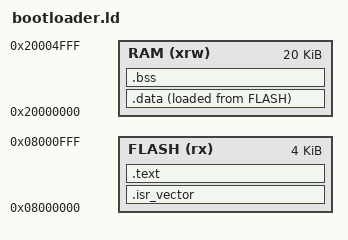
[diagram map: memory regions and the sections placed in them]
/* GX100 bootloader: first 4 KB of flash (see Firmware/App/Inc/gx100_boot.h). */
ENTRY(Reset_Handler)

MEMORY
{
  FLASH (rx)  : ORIGIN = 0x08000000, LENGTH = 4K
  RAM   (xrw) : ORIGIN = 0x20000000, LENGTH = 20K
}

_estack = ORIGIN(RAM) + LENGTH(RAM);

SECTIONS
{
  .isr_vector : { KEEP(*(.isr_vector)) } > FLASH

  .text :
  {
    . = ALIGN(4);
    *(.text*)
    *(.rodata*)
    . = ALIGN(4);
  } > FLASH

  _sidata = LOADADDR(.data);
  .data :
  {
    . = ALIGN(4);
    _sdata = .;
    *(.data*)
    . = ALIGN(4);
    _edata = .;
  } > RAM AT > FLASH

  .bss (NOLOAD) :
  {
    . = ALIGN(4);
    _sbss = .;
    *(.bss*)
    *(COMMON)
    . = ALIGN(4);
    _ebss = .;
  } > RAM

  /DISCARD/ : { *(.ARM.exidx*) *(.ARM.extab*) }
}
